# STMP3770 register map
Vendor: Freescale Semiconductor (NXP); Series: STMP37xx; File version: 1.0
CPU: other r0p0, little endian, no MPU, no FPU, 2 interrupt priority bits
Registers are 32-bit, read-write, reset 0x0 unless marked. A register's access mark holds for its fields unless they carry their own. Offsets are from the block's base; [hi:lo] are bit positions; {n}, {i} and the like mark numbered series.

## GPMI — NAND Flash 通用接口控制器，支持 NAND/ATA 模式，集成 ECC(BCH/ECC8) 纠错引擎，提供 DMA 数据传输、时序配置与命令执行功能。
Base 0x8000C000
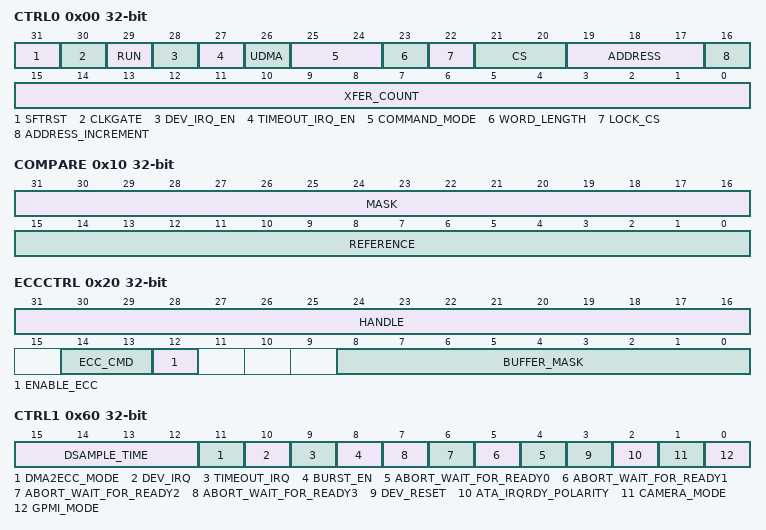
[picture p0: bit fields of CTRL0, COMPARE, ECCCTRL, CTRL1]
0x00 CTRL0 — GPMI 控制寄存器 0，配置单次命令传输的核心参数并启动执行。
  [31] SFTRST — 软复位：RUN=正常工作；RESET=复位整个 GPMI 模块。
    0=RUN; 1=RESET
  [30] CLKGATE — 时钟门控：RUN=正常运行；NO_CLKS=关闭 GPMI 时钟以节能。
    0=RUN; 1=NO_CLKS
  [29] RUN — 命令执行状态：IDLE=空闲；BUSY=命令正在执行，写 1 启动命令。
    0=IDLE; 1=BUSY
  [28] DEV_IRQ_EN — 设备就绪中断使能，置 1 允许设备就绪中断上报。
  [27] TIMEOUT_IRQ_EN — 设备忙等待超时中断使能，置 1 允许超时中断上报。
  [26] UDMA — UDMA 模式使能：DISABLED=禁用；ENABLED=启用 Ultra DMA 传输。
    0=DISABLED; 1=ENABLED
  [25:24] COMMAND_MODE — 命令模式：WRITE=写数据；READ=读数据；READ_AND_COMPARE=读并比较；WAIT_FOR_READY=等待设备就绪。
    0=WRITE; 1=READ; 2=READ_AND_COMPARE; 3=WAIT_FOR_READY
  [23] WORD_LENGTH — 数据位宽：_16_BIT=16 位；_8_BIT=8 位。
    0=_16_BIT; 1=_8_BIT
  [22] LOCK_CS — 片选锁定使能：DISABLED=传输结束后自动释放 CS；ENABLED=锁定 CS 直到显式释放。
    0=DISABLED; 1=ENABLED
  [21:20] CS — 片选信号编号，选择当前操作的 NAND 设备(0~3)。
  [19:17] ADDRESS — NAND 地址类型：NAND_DATA=数据寄存器；NAND_CLE=命令锁存使能；NAND_ALE=地址锁存使能。
    0=NAND_DATA; 1=NAND_CLE; 2=NAND_ALE
  [16] ADDRESS_INCREMENT — 地址自增使能：DISABLED=禁止自增；ENABLED=每传输一个字后地址自动递增。
    0=DISABLED; 1=ENABLED
  [15:0] XFER_COUNT — 本次命令传输的字节数，0 表示 65536 字节。
0x10 COMPARE — 读数据比较寄存器，用于 READ_AND_COMPARE 模式下的数据校验。
  [31:16] MASK — 比较掩码，仅掩码为 1 的位参与比较。
  [15:0] REFERENCE — 读数据比较的参考值。
0x20 ECCCTRL — 集成 ECC 控制寄存器，配置 ECC 引擎的操作模式与数据缓冲。
  [31:16] HANDLE — ECC 操作句柄标识，用于关联本次 ECC 传输的上下文。
  [14:13] ECC_CMD — ECC 命令：DECODE_4_BIT=4 位解码；ENCODE_4_BIT=4 位编码；DECODE_8_BIT=8 位解码；ENCODE_8_BIT=8 位编码。
    0=DECODE_4_BIT; 1=ENCODE_4_BIT; 2=DECODE_8_BIT; 3=ENCODE_8_BIT
  [12] ENABLE_ECC — ECC 使能：ENABLE=启用 ECC 编解码(写 1)；DISABLE=关闭 ECC(写 0)。
    1=ENABLE; 0=DISABLE
  [8:0] BUFFER_MASK — ECC 数据缓冲掩码，选择参与 ECC 编解码的缓冲单元(BUFFER0~7、BCH_PAGE、BCH_AUXONLY)。
    0x100=BCH_AUXONLY; 0x1FF=BCH_PAGE; 128=BUFFER7; 64=BUFFER6; 32=BUFFER5; 16=BUFFER4; 8=BUFFER3; 4=BUFFER2; 2=BUFFER1; 1=BUFFER0
0x30 ECCCOUNT — 集成 ECC 传输计数寄存器，指定 ECC 编解码的数据量。
  [15:0] COUNT — ECC 编解码的字节数，0 表示 65536 字节。
0x40 PAYLOAD — DMA 主数据(Payload)缓冲地址寄存器，存放 NAND 页数据(数据区)的物理地址。
  [31:2] ADDRESS — Payload 数据缓冲的物理地址高 30 位(bit 31:2)，低 2 位固定为 0。
0x50 AUXILIARY — DMA 辅助数据(Auxiliary)缓冲地址寄存器，存放 NAND 备用区(如 OOB/元数据)的物理地址。
  [31:2] ADDRESS — Auxiliary 数据缓冲的物理地址高 30 位(bit 31:2)，低 2 位固定为 0。
0x60 CTRL1 — GPMI 控制寄存器 1，配置工作模式、中断、采样时序与设备复位等全局参数。
  [15:12] DSAMPLE_TIME — 读数据采样延时，以 GPMI 时钟周期为单位调整读数据采样时刻，用于时序补偿。
  [11] DMA2ECC_MODE — DMA 到 ECC 直通模式使能，控制 DMA 数据是否直接送入 ECC 引擎处理。
  [10] DEV_IRQ — 设备就绪中断状态位，写 1 清零。
  [9] TIMEOUT_IRQ — 设备忙等待超时中断状态位，写 1 清零。
  [8] BURST_EN — DMA 突发传输(Burst)使能。
  [n+4] ABORT_WAIT_FOR_READY{n} (n=0..3) — 强制中止设备 {n} 的等待就绪操作。
  [3] DEV_RESET — 设备复位控制：ENABLED=释放复位、设备正常工作(写 0)；DISABLED=置位复位、设备被复位(写 1)。
    0=ENABLED; 1=DISABLED
  [2] ATA_IRQRDY_POLARITY — ATA IRQ/RDY 信号极性：ACTIVELOW=低电平有效；ACTIVEHIGH=高电平有效。
    0=ACTIVELOW; 1=ACTIVEHIGH
  [1] CAMERA_MODE — Camera 模式使能，控制 GPMI 是否工作于 Camera 接口模式。
  [0] GPMI_MODE — GPMI 工作模式：NAND=NAND Flash 模式；ATA=ATA 硬盘模式。
    0=NAND; 1=ATA
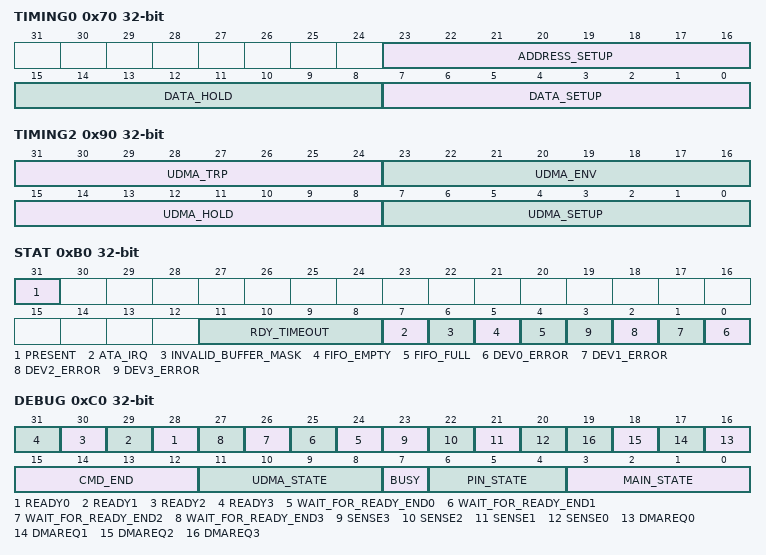
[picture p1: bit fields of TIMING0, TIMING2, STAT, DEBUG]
0x70 TIMING0 — NAND 时序寄存器 0，配置 NAND 读写的基础时序参数。
  [23:16] ADDRESS_SETUP — 地址建立时间，控制 ALE/CLE 有效到 WE/RE 有效之间的 GPMI 时钟周期数。
  [15:8] DATA_HOLD — 数据保持时间，控制数据稳定后 WE/RE 保持有效的 GPMI 时钟周期数。
  [7:0] DATA_SETUP — 数据建立时间，控制 WE/RE 有效到数据稳定所需的 GPMI 时钟周期数。
0x80 TIMING1 — NAND 时序寄存器 1，配置设备忙等待超时时间。
  [31:16] DEVICE_BUSY_TIMEOUT — 设备忙等待超时计数，以 GPMI 时钟周期为单位设定最大等待时间。
0x90 TIMING2 — UDMA 时序寄存器 2，配置 Ultra DMA 模式下的专用时序参数。
  [31:24] UDMA_TRP — UDMA 恢复时间，控制 UDMA 传输之间所需的最小间隔周期数。
  [23:16] UDMA_ENV — UDMA 包络时间，控制 UDMA 传输包络信号的宽度。
  [15:8] UDMA_HOLD — UDMA 保持时间，控制 UDMA 传输结束后信号的保持周期数。
  [7:0] UDMA_SETUP — UDMA 建立时间，控制 UDMA 传输开始前信号的建立周期数。
0xA0 DATA — DMA 数据传送寄存器，用于 APB 总线直接读写 NAND 数据(非 DMA 模式或调试用途)。
  [31:0] DATA — 32 位数据端口，通过 APB 总线直接读写 NAND 数据。
0xB0 STAT — GPMI 状态寄存器，反映设备错误、FIFO 状态、中断与模块存在性。
  [31] PRESENT — GPMI 模块存在性：UNAVAILABLE=不存在；AVAILABLE=存在。
    0=UNAVAILABLE; 1=AVAILABLE
  [11:8] RDY_TIMEOUT — 就绪超时状态，指示哪个设备发生了 RDY 超时(位映射)。
  [7] ATA_IRQ — ATA 设备中断请求状态。
  [6] INVALID_BUFFER_MASK — ECC 缓冲掩码无效标志，指示 ECCCTRL 中 BUFFER_MASK 配置非法。
  [5] FIFO_EMPTY — FIFO 空状态：NOT_EMPTY=非空；EMPTY=已空。
    0=NOT_EMPTY; 1=EMPTY
  [4] FIFO_FULL — FIFO 满状态：NOT_FULL=未满；FULL=已满。
    0=NOT_FULL; 1=FULL
  [n] DEV{n}_ERROR (n=0..3) — 设备 {n} 错误标志，指示该设备发生错误。
0xC0 DEBUG ro — GPMI 调试信息寄存器，提供主状态机、引脚状态机、DMA 请求与设备就绪等实时调试信号。
  [n+28] READY{n} (n=0..3) — 设备 {n} 的就绪(READY)信号输入状态。
  [n+24] WAIT_FOR_READY_END{n} (n=0..3) — 设备 {n} 的等待就绪结束标志。
  [23] SENSE3 — 设备 3 的 sense 信号状态。
  [22] SENSE2 — 设备 2 的 sense 信号状态。
  [21] SENSE1 — 设备 1 的 sense 信号状态。
  [20] SENSE0 — 设备 0 的 sense 信号状态(用于检测设备就绪/中断)。
  [n+16] DMAREQ{n} (n=0..3) — 设备 {n} 的 DMA 请求信号状态。
  [15:12] CMD_END — 命令结束状态，反映各通道命令完成情况的位映射。
  [11:8] UDMA_STATE — UDMA 状态机当前状态值。
  [7] BUSY — GPMI 忙标志：DISABLED=空闲；ENABLED=忙。
    0=DISABLED; 1=ENABLED
  [6:4] PIN_STATE — 引脚状态机状态：PSM_IDLE~PSM_DONE，反映外部引脚时序状态。
    0=PSM_IDLE; 1=PSM_BYTCNT; 2=PSM_ADDR; 3=PSM_STALL; 4=PSM_STROBE; 5=PSM_ATARDY; 6=PSM_DHOLD; 7=PSM_DONE
  [3:0] MAIN_STATE — 主状态机状态：MSM_IDLE~MSM_DONE，反映 GPMI 内部命令执行流程。
    0=MSM_IDLE; 1=MSM_BYTCNT; 2=MSM_WAITFE; 3=MSM_WAITFR; 4=MSM_DMAREQ; 5=MSM_DMAACK; 6=MSM_WAITFF; 7=MSM_LDFIFO; 8=MSM_LDDMAR; 9=MSM_RDCMP; 10=MSM_DONE
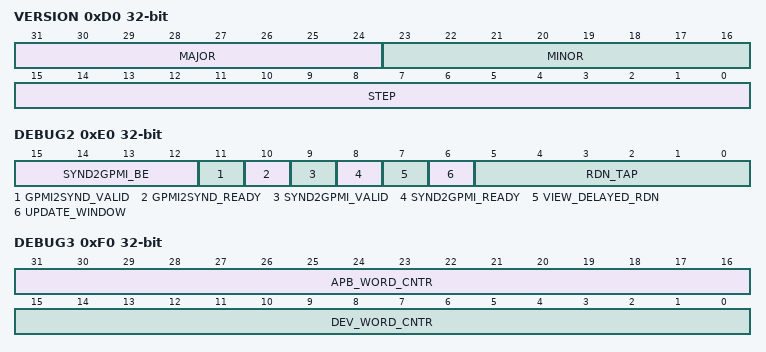
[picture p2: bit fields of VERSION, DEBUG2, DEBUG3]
0xD0 VERSION ro — GPMI 版本寄存器，记录模块的硬件版本号。
  [31:24] MAJOR — 主版本号。
  [23:16] MINOR — 次版本号。
  [15:0] STEP — 步进版本号，标识当前硬件的步进修订。
0xE0 DEBUG2 ro — GPMI 调试信息寄存器 2，提供读数据采样 DLL 抽头、同步器握手与字节使能等调试信号。
  [15:12] SYND2GPMI_BE — Syndrome 到 GPMI 的字节使能信号，指示有效字节位置。
  [11] GPMI2SYND_VALID — GPMI 到 Syndrome 的 VALID 握手信号状态。
  [10] GPMI2SYND_READY — GPMI 到 Syndrome 的 READY 握手信号状态。
  [9] SYND2GPMI_VALID — Syndrome 到 GPMI 的 VALID 握手信号状态。
  [8] SYND2GPMI_READY — Syndrome 到 GPMI 的 READY 握手信号状态。
  [7] VIEW_DELAYED_RDN — 延时读数据采样视图使能，用于观察经 DLL 延时后的读数据采样信号。
  [6] UPDATE_WINDOW — DLL 更新窗口标志，指示 DLL 是否处于允许更新的时间窗口。
  [5:0] RDN_TAP — 读数据采样 DLL 抽头值，反映当前 DLL 延时链的抽头位置。
0xF0 DEBUG3 ro — GPMI 调试信息寄存器 3，提供设备侧与 APB 侧的字计数器。
  [31:16] APB_WORD_CNTR — APB 侧已传输字数计数器，反映 APB 总线侧传输的字数。
  [15:0] DEV_WORD_CNTR — 设备侧已传输字数计数器，反映与 NAND 设备之间传输的字数。
